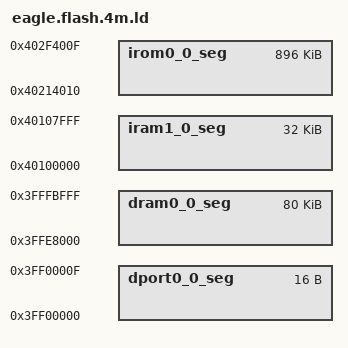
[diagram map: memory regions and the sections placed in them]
/* This linker script generated from xt-genldscripts.tpp for LSP . */
/* Linker Script for ld -N */
MEMORY
{
  dport0_0_seg :                        org = 0x3FF00000, len = 0x10
  dram0_0_seg :                         org = 0x3FFE8000, len = 0x14000
  iram1_0_seg :                         org = 0x40100000, len = 0x8000
  irom0_0_seg :                         org = 0x40214010, len = 0xE0000
}

PROVIDE ( _SPIFFS_start = 0x29B000 );
PROVIDE ( _SPIFFS_end = 0x3FC000 );
PROVIDE ( _SPIFFS_page = 0x100 );
PROVIDE ( _SPIFFS_block = 0x2000 );

INCLUDE "eagle.app.v6.common.ld"
